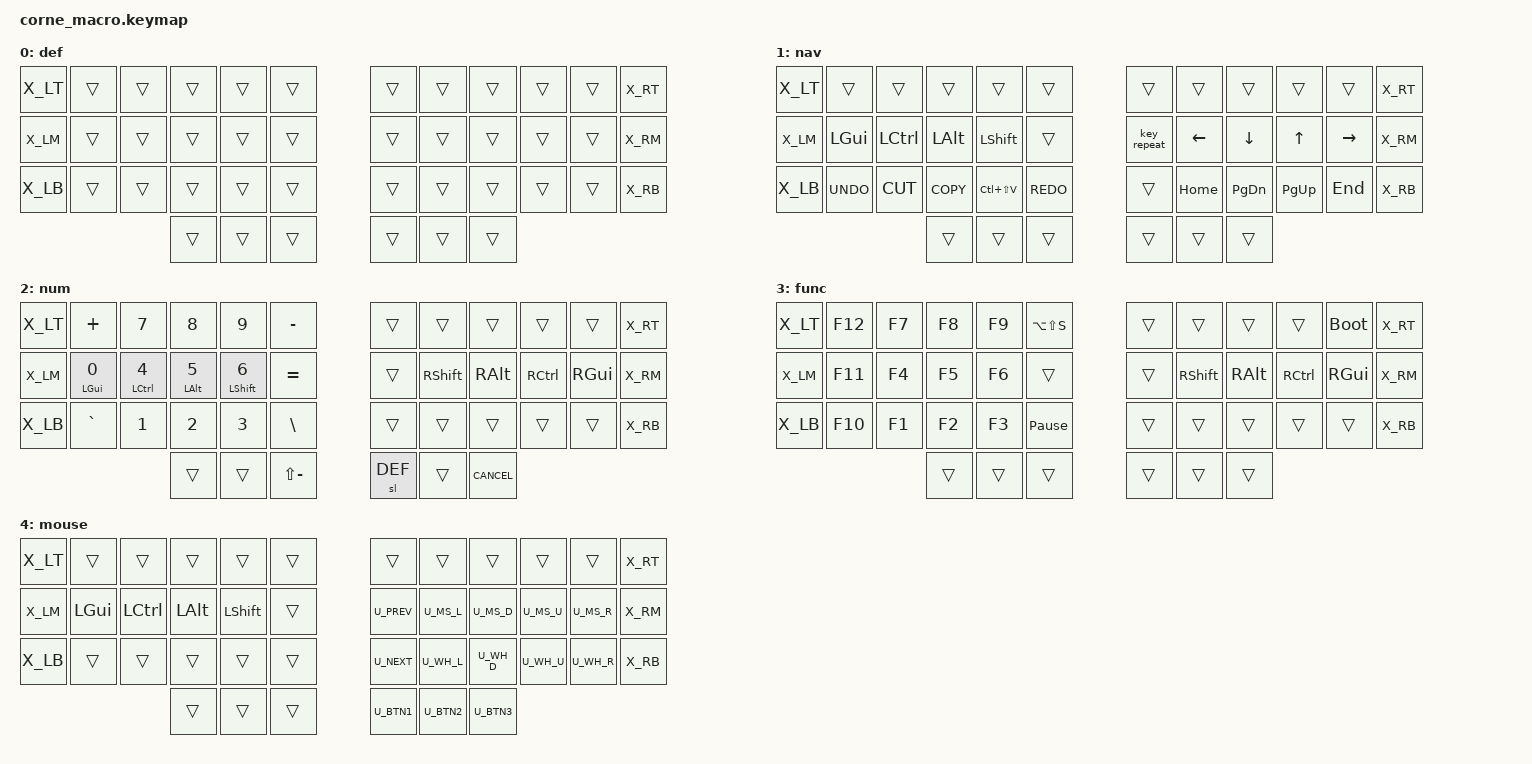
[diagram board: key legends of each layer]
#include <behaviors.dtsi>
#include <dt-bindings/zmk/keys.h>
#include <dt-bindings/zmk/bt.h>
#include <dt-bindings/zmk/outputs.h>

#if CONFIG_WIRELESS
    #include <dt-bindings/zmk/bt.h>
    #define _BT_SEL_KEYS_ &bt BT_SEL 0 &bt BT_SEL 1 &bt BT_SEL 2 &bt BT_SEL 3 &bt BT_CLR
#else
    #define _BT_SEL_KEYS_ &trans &trans &trans &trans &trans
#endif

#include "../zmk-nodefree-config/helper.h"
#include "../zmk-nodefree-config/keypos_def/keypos_36keys.h"

#define DEF     0
#define NAV     1
#define NUM     2
#define FUNC    3
#define MOUSE   4
#define MEDIA   5
// #define SYS     6

/* Global settings */

#define QUICK_TAP_MS 175

&lt {  // layer-tap
    tapping-term-ms = <200>;
    quick_tap_ms = <QUICK_TAP_MS>;
    flavor = "balanced";
};

&sk {  // sticky-key config
    release-after-ms = <900>;  // release after 0.6s
    quick-release;             // no double capitalization when rolling keys
};

&sl {  // sticky-layer config
    ignore-modifiers;          // allow chording sticky mods & layers
};

/* Homerow mods from urob base.keymap */

#define KEYS_L LT0 LT1 LT2 LT3 LT4 LM0 LM1 LM2 LM3 LM4 LB0 LB1 LB2 LB3 LB4  // left hand
#define KEYS_R RT0 RT1 RT2 RT3 RT4 RM0 RM1 RM2 RM3 RM4 RB0 RB1 RB2 RB3 RB4  // right hand
#define THUMBS LH2 LH1 LH0 RH0 RH1 RH2                                      // thumbs

#define MAKE_HRM(NAME, HOLD, TAP, TRIGGER_POS) \
    ZMK_BEHAVIOR(NAME, hold_tap, \
        flavor = "balanced"; \
        tapping-term-ms = <280>; \
        quick-tap-ms = <QUICK_TAP_MS>; \
        require-prior-idle-ms = <150>; \
        bindings = <HOLD>, <TAP>; \
        hold-trigger-key-positions = <TRIGGER_POS>; \
        hold-trigger-on-release; \
    )
MAKE_HRM(hml, &kp, &kp, KEYS_R THUMBS)  // left-hand HRMs
MAKE_HRM(hmr, &kp, &kp, KEYS_L THUMBS)  // right-hand HRMs
MAKE_HRM(hml_repeat, &kp, &key_repeat, KEYS_R THUMBS) // for HRM combo

// Include after global settings 
#include "includes/morphs.dtsi"
#include "includes/mouse.dtsi"
#include "includes/combos.dtsi" // requires layer aliases, HRMs 
#include "includes/smarts.dtsi" // requires global settings
#include "includes/extra_keys.h"

// aliases
#define XXX &none
#define ___ &trans
#define CANCEL    &kp K_CANCEL  // cancel caps-word, num-word and smart-mouse
#define PASTE     &kp LC(LS(V))
#define PRNT_MODE &kp LA(LS(S)) // bound in swayLm

ZMK_LAYER(def,
//╭──────╮╭──────────────┬──────────────┬──────────────┬──────────────┬──────────────╮    ╭──────────────┬──────────────┬──────────────┬──────────────┬──────────────╮╭──────╮
    X_LT    ___            ___            ___            ___            ___                 ___            ___            ___            ___            ___            X_RT
    X_LM    ___            ___            ___            ___            ___                 ___            ___            ___            ___            ___            X_RM
    X_LB    ___            ___            ___            ___            ___                 ___            ___            ___            ___            ___            X_RB
//├──────┤╰──────────────┴──────────────┴──────────────┼──────────────┼──────────────┤    ├──────────────┴──────────────┴──────────────┼──────────────┼──────────────╯├──────┤
                                          ___            ___            ___                 ___            ___            ___                         
//╰──────╯                              ╰──────────────┴──────────────┴──────────────╯    ╰──────────────┴──────────────┴──────────────╯                              ╰──────╯
)
ZMK_LAYER(nav,
//╭──────╮╭──────────────┬──────────────┬──────────────┬──────────────┬──────────────╮    ╭──────────────┬──────────────┬──────────────┬──────────────┬──────────────╮╭──────╮
    X_LT    ___            ___            ___            ___            ___                 ___            ___            ___            ___            ___             X_RT  
    X_LM    &kp LGUI       &kp LCTL       &kp LALT       &kp LSHIFT     ___                 &key_repeat    &kp LEFT       &kp DOWN       &kp UP         &kp RIGHT       X_RM  
    X_LB    &kp K_UNDO     &kp K_CUT      &kp K_COPY     PASTE          &kp K_REDO          ___            &kp HOME       &kp PG_DN      &kp PG_UP      &kp END         X_RB  
//├──────┤╰──────────────┴──────────────┴──────────────┼──────────────┼──────────────┤    ├──────────────┴──────────────┴──────────────┼──────────────┼──────────────╯├──────┤
                                          ___            ___            ___                 ___            ___            ___                                             
//╰──────╯                              ╰──────────────┴──────────────┴──────────────╯    ╰──────────────┴──────────────┴──────────────╯                              ╰──────╯
)
ZMK_LAYER(num,
//╭──────╮╭──────────────┬──────────────┬──────────────┬──────────────┬──────────────╮    ╭──────────────┬──────────────┬──────────────┬──────────────┬──────────────╮╭──────╮
    X_LT    &kp PLUS       &kp N7         &kp N8         &kp N9         &kp MINUS            ___            ___           ___            ___            ___             X_RT  
    X_LM    &hml LGUI N0   &hml LCTL N4   &hml LALT N5   &hml LSHIFT N6 &kp EQUAL            ___            &kp RSHIFT    &kp RALT       &kp RCTL       &kp RGUI        X_RM  
    X_LB    &kp GRAVE      &kp N1         &kp N2         &kp N3         &kp BSLH             ___            ___           ___            ___            ___             X_RB  
//├──────┤╰──────────────┴──────────────┴──────────────┼──────────────┼──────────────┤    ├──────────────┴──────────────┴──────────────┼──────────────┼──────────────╯├──────┤
                                          ___            ___            &kp LS(MINUS)        &sl DEF        ___           CANCEL                                          
//╰──────╯                              ╰──────────────┴──────────────┴──────────────╯    ╰──────────────┴──────────────┴──────────────╯                              ╰──────╯
)
ZMK_LAYER(func,
//╭──────╮╭──────────────┬──────────────┬──────────────┬──────────────┬──────────────╮    ╭──────────────┬──────────────┬──────────────┬──────────────┬──────────────╮╭──────╮
    X_LT    &kp F12        &kp F7         &kp F8         &kp F9         PRNT_MODE           ___            ___            ___            ___            &bootloader     X_RT
    X_LM    &kp F11        &kp F4         &kp F5         &kp F6         ___                 ___            &kp RSHIFT     &kp RALT       &kp RCTL       &kp RGUI        X_RM
    X_LB    &kp F10        &kp F1         &kp F2         &kp F3         &kp PAUSE_BREAK     ___            ___            ___            ___            ___             X_RB
//├──────┤╰──────────────┴──────────────┴──────────────┼──────────────┼──────────────┤    ├──────────────┴──────────────┴──────────────┼──────────────┼──────────────╯├──────┤
                                          ___            ___            ___                 ___             ___            ___                                          
//╰──────╯                              ╰──────────────┴──────────────┴──────────────╯    ╰──────────────┴──────────────┴──────────────╯                              ╰──────╯
)
ZMK_LAYER(mouse,
//╭──────╮╭──────────────┬──────────────┬──────────────┬──────────────┬──────────────╮    ╭──────────────┬──────────────┬──────────────┬──────────────┬──────────────╮╭──────╮
    X_LT    ___            ___            ___            ___            ___                 ___            ___            ___            ___           ___              X_RT  
    X_LM    &kp LGUI       &kp LCTL       &kp LALT       &kp LSHIFT     ___                 U_PREV         U_MS_L         U_MS_D         U_MS_U        U_MS_R           X_RM  
    X_LB    ___            ___            ___            ___            ___                 U_NEXT         U_WH_L         U_WH_D         U_WH_U        U_WH_R           X_RB  
//├──────┤╰──────────────┴──────────────┴──────────────┼──────────────┼──────────────┤    ├──────────────┴──────────────┴──────────────┼──────────────┼──────────────╯├──────┤
                                          ___            ___            ___                 U_BTN1         U_BTN2         U_BTN3                                          
//╰──────╯                              ╰──────────────┴──────────────┴──────────────╯    ╰──────────────┴──────────────┴──────────────╯                              ╰──────╯
)
ZMK_LAYER_3(media,
//╭──────╮╭──────────────┬──────────────┬──────────────┬──────────────┬──────────────╮    ╭──────────────┬──────────────┬──────────────┬──────────────┬──────────────╮╭──────╮
    X_LT    &bootloader    ___            ___            &out OUT_USB   &out OUT_BLE        ___            &kp C_BRI_DN   &kp C_BRI_UP   ___            ___             X_RT
    X_LM    &kp LGUI       &kp LCTL       &kp LALT       &kp LSHIFT      ___                &kp C_MUTE     &kp C_PREV     &kp K_VOL_DN   &kp K_VOL_UP   &kp C_NEXT      X_RM
    X_LB    &bt BT_CLR     &bt BT_SEL 0   &bt BT_SEL 1   &bt BT_SEL 2    &bt BT_SEL 3       ___            ___             ___            ___           ___             X_RB
//├──────┤╰──────────────┴──────────────┴──────────────┼──────────────┼──────────────┤    ├──────────────┴──────────────┴──────────────┼──────────────┼──────────────╯├──────┤
                                           ___            ___           ___                 &kp C_STOP     &kp C_PP       &kp C_MUTE                                    
//╰──────╯                              ╰──────────────┴──────────────┴──────────────╯    ╰──────────────┴──────────────┴──────────────╯                              ╰──────╯
// , &inc_dec_kp C_BRI_DN C_BRI_UP
, &inc_dec_kp C_VOL_UP C_VOL_DN
)
// ZMK_LAYER(sys,
// //╭──────╮ ╭─────────────┬─────────────┬─────────────┬─────────────┬─────────────╮  ╭─────────────┬─────────────┬─────────────┬─────────────┬─────────────╮ ╭──────╮
//     X_LT                                _BT_SEL_KEYS_                                 ___           ___           ___           ___           ___             X_RT
//     X_LM     ___           ___           ___           ___           &bootloader      &bootloader   ___           ___           ___           ___             X_RM
//     X_LB     ___           ___           ___           ___           &sys_reset       &sys_reset    ___           ___           ___           ___             X_RB
// //├──────┤ ╰─────────────┼─────────────┴─────────────┼─────────────┼─────────────┤  ├─────────────┼─────────────┼─────────────┴───────────────────────────╯ ├──────┤
//                                                        ___           ___              ___           ___                                                       
// //╰──────╯                                           ╰─────────────┴─────────────╯  ╰─────────────┴─────────────╯                                           ╰──────╯
// )
// vim: nowrap: ft=c: fdm=indent: expandtab:
